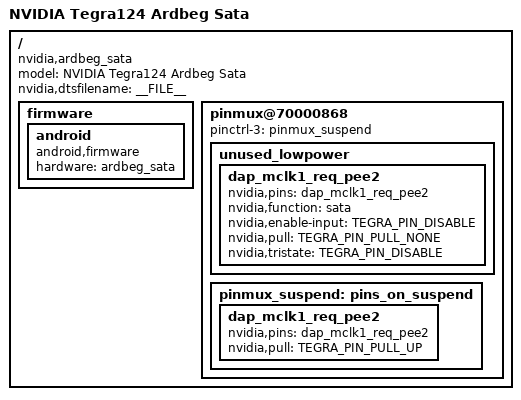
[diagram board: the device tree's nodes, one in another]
#include "tegra124-ardbeg-e1780-1000-a03-00.dts"

/ {
	model = "NVIDIA Tegra124 Ardbeg Sata";
	compatible = "nvidia,ardbeg_sata", "nvidia,tegra124";
	nvidia,dtsfilename = __FILE__;

	firmware {
		android {
			compatible = "android,firmware";
			hardware = "ardbeg_sata";
		};
	};

	pinmux@70000868 {
		pinctrl-names = "default", "drive", "unused", "suspend";
		pinctrl-3 = <&pinmux_suspend>;

		/* Change the pin dap_mclk1_req to required configurations */
		unused_lowpower {
			dap_mclk1_req_pee2 {
				nvidia,pins = "dap_mclk1_req_pee2";
				nvidia,function = "sata";
				nvidia,enable-input = <TEGRA_PIN_DISABLE>;
				nvidia,pull = <TEGRA_PIN_PULL_NONE>;
				nvidia,tristate = <TEGRA_PIN_DISABLE>;
			};
		};

		/* On suspend, make dap_mclk1_req to pull up */
		pinmux_suspend: pins_on_suspend {
			dap_mclk1_req_pee2 {
				nvidia,pins = "dap_mclk1_req_pee2";
				nvidia,pull = <TEGRA_PIN_PULL_UP>;
			};
		};
	};
};
